AUTOSAR XML (schema 4-3-0)
standard types defined: uint16, uint32, uint8, uint16_DataConstr, uint32_DataConstr, uint8_DataConstr
package /ComponentTypes/HkmcRadarAdapSWC
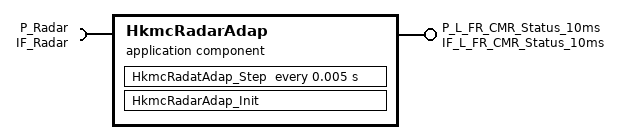
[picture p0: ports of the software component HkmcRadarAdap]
  application sw component type HkmcRadarAdap
    provide port P_L_FR_CMR_Status_10ms: nonqueued-sender-com-spec{data-element=DE_HkmcRadarAdapOutput, init-value=constant-reference=CS_RadarAdap_L_FR_CMR_Status_10ms}, provided-interface=IF_L_FR_CMR_Status_10ms
    require port P_Radar: nonqueued-receiver-com-spec{data-element=DE_HkmcRadarAdapInput, filter=data-filter-type=ALWAYS, init-value=constant-reference=CS_RadarAdap_Radar}, required-interface=IF_Radar
    behavior HkmcRadarAdap_InternalBehavior
      init event HkmcRadarAdap_InitEvent: start-on-event=HkmcRadarAdap_Init
      timing event HkmcRadatAdap_Step_TE: start-on-event=HkmcRadatAdap_Step, period=0.005
      runnable HkmcRadarAdap_Init
        data-receive-point-by-arguments:
          access REC_P_Radar_DE_HkmcRadarAdapInput: accessed-variable=P_Radar.DE_HkmcRadarAdapInput
        data-send-points:
          access SEND_P_L_FR_CMR_Status_10ms_DE_HkmcRadarAdapOutput: accessed-variable=P_L_FR_CMR_Status_10ms.DE_HkmcRadarAdapOutput
      runnable HkmcRadatAdap_Step
        data-receive-point-by-arguments:
          access REC_P_Radar_DE_HkmcRadarAdapInput: accessed-variable=P_Radar.DE_HkmcRadarAdapInput
        data-send-points:
          access SEND_P_L_FR_CMR_Status_10ms_DE_HkmcRadarAdapOutput: accessed-variable=P_L_FR_CMR_Status_10ms.DE_HkmcRadarAdapOutput
  swc implementation HkmcRadarAdap_Implementation: behavior=HkmcRadarAdap_InternalBehavior
    code-descriptors:
      code Default: artifact-descriptors=autosar-engineering-object={short-label=Default, category=SWSRC}
package /ComponentTypes/HkmcRadarAdapSWC/Constants
  constant specification CS_RadarAdap_L_FR_CMR_Status_10ms: value-spec=fields=[L_FR_CMR_Status_SAS_AnglVal:0, L_FR_CMR_Status_YawRtCompensated:0, L_FR_CMR_Status_LatAccelVal:0, L_FR_CMR_Status_LongAccelVal:0, L_FR_CMR_Status_EstVehSpdVal:0, L_FR_CMR_Status_EstVehSpdFailure:0, L_FR_CMR_Status_EstVehDirection:0, L_ENG_EngSta:0, L_HCU_HevRdySta:0, L_VCU_EVRdySta:0, L_ENG_IgnOnSta:0, CLU_OdoVal:0]
  constant specification CS_RadarAdap_Radar: value-spec=fields=[SAS_AnglVal:0, ESC_YawRtVal:0, ESC_LatAccelVal:0, ESC_LongAccelVal:0, longitudinalSpeed:0, longitudinalSpeedQual:0, WHL_DirFLVal:0, WHL_DirFRVal:0, WHL_DirRLVal:0, WHL_DirRRVal:0, ENG_EngSta:0, HCU_HevRdySta:0, VCU_EVRdySta:0, ENG_IgnOnSta:0, CLU_OdoVal:0]
package /ComponentTypes/HkmcRadarAdapSWC/DataTypes
  impl type L_FR_CMR_Status_10ms: category=STRUCTURE, type-emitter=RTE
    12 x element, all with category=TYPE_REFERENCE:
      L_FR_CMR_Status_SAS_AnglVal: implementation-data-type=uint16
      L_FR_CMR_Status_YawRtCompensated: implementation-data-type=uint16
      L_FR_CMR_Status_LatAccelVal: implementation-data-type=uint16
      L_FR_CMR_Status_LongAccelVal: implementation-data-type=uint16
      L_FR_CMR_Status_EstVehSpdVal: implementation-data-type=uint16
      L_FR_CMR_Status_EstVehSpdFailure: implementation-data-type=uint8
      L_FR_CMR_Status_EstVehDirection: implementation-data-type=uint8
      L_ENG_EngSta: implementation-data-type=uint8
      L_HCU_HevRdySta: implementation-data-type=uint8
      L_VCU_EVRdySta: implementation-data-type=uint8
      L_ENG_IgnOnSta: implementation-data-type=uint8
      CLU_OdoVal: implementation-data-type=uint8
  impl type Radar: category=STRUCTURE, sw-calibration-access=READ-ONLY, type-emitter=RTE
    15 x element, all with category=TYPE_REFERENCE:
      SAS_AnglVal: implementation-data-type=uint8
      ESC_YawRtVal: implementation-data-type=uint8
      ESC_LatAccelVal: implementation-data-type=uint8
      ESC_LongAccelVal: implementation-data-type=uint16
      longitudinalSpeed: implementation-data-type=uint8
      longitudinalSpeedQual: implementation-data-type=uint8
      WHL_DirFLVal: implementation-data-type=uint8
      WHL_DirFRVal: implementation-data-type=uint8
      WHL_DirRLVal: implementation-data-type=uint8
      WHL_DirRRVal: implementation-data-type=uint8
      ENG_EngSta: implementation-data-type=uint8
      HCU_HevRdySta: implementation-data-type=uint8
      VCU_EVRdySta: implementation-data-type=uint8
      ENG_IgnOnSta: implementation-data-type=uint8
      CLU_OdoVal: implementation-data-type=uint32
package /ComponentTypes/HkmcRadarAdapSWC/PortInterfaces
  sender receiver interface IF_L_FR_CMR_Status_10ms: invalidation-policy{data-element=DE_HkmcRadarAdapOutput, handle-invalid=DONT-INVALIDATE}
    data DE_HkmcRadarAdapOutput: type=L_FR_CMR_Status_10ms
  sender receiver interface IF_Radar: invalidation-policy{data-element=DE_HkmcRadarAdapInput, handle-invalid=DONT-INVALIDATE}
    data DE_HkmcRadarAdapInput: type=Radar
